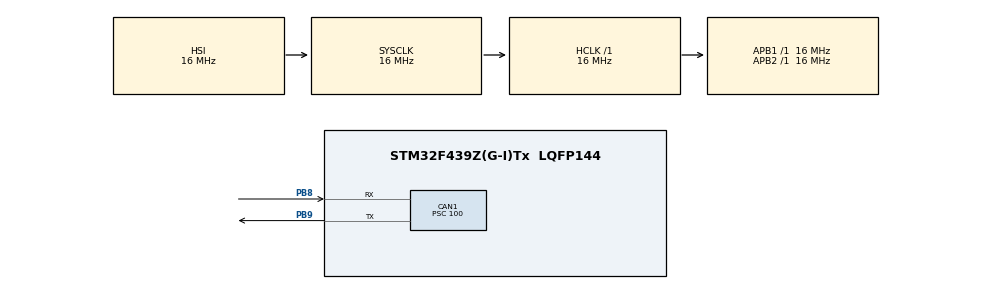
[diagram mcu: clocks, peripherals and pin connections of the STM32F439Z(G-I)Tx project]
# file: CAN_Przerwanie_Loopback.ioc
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CAN1.BS1=CAN_BS1_13TQ
CAN1.BS2=CAN_BS2_2TQ
CAN1.CalculateBaudRate=10000
CAN1.CalculateTimeBit=100000.00
CAN1.CalculateTimeQuantum=6250.0
CAN1.Mode=CAN_MODE_LOOPBACK
CAN1.Prescaler=100
Mcu.Family=STM32F4
Mcu.Name=STM32F439Z(G-I)Tx
Mcu.Package=LQFP144
NVIC.CAN1_RX0_IRQn=true\:0\:0\:false\:false\:true\:true\:true
NVIC.PriorityGroup=NVIC_PRIORITYGROUP_4
PA13.Mode=Serial_Wire
PA13.Signal=SYS_JTMS-SWDIO
PA14.Mode=Serial_Wire
PA14.Signal=SYS_JTCK-SWCLK
PB8.Mode=CAN_Activate
PB8.Signal=CAN1_RX
PB9.Mode=CAN_Activate
PB9.Signal=CAN1_TX
ProjectManager.HeapSize=0x200
ProjectManager.StackSize=0x400
ProjectManager.TargetToolchain=STM32CubeIDE
RCC.48MHZClocksFreq_Value=48000000
RCC.AHBFreq_Value=16000000
RCC.APB1Freq_Value=16000000
RCC.APB2Freq_Value=16000000
RCC.CortexFreq_Value=16000000
RCC.HSE_VALUE=25000000
RCC.HSI_VALUE=16000000
RCC.LSE_VALUE=32768
RCC.SYSCLKFreq_VALUE=16000000
RCC.VCOOutputFreq_Value=192000000
board=custom

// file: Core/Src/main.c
/* USER CODE BEGIN Header */
/**
  ******************************************************************************
  * @file           : main.c
  * @brief          : Main program body
  ******************************************************************************
  * @attention
  *
  * <h2><center>&copy; Copyright (c) 2021 STMicroelectronics.
  * All rights reserved.</center></h2>
  *
  * This software component is licensed by ST under BSD 3-Clause license,
  * the "License"; You may not use this file except in compliance with the
  * License. You may obtain a copy of the License at:
  *                        opensource.org/licenses/BSD-3-Clause
  *
  ******************************************************************************
  */
/* USER CODE END Header */
#include "main.h"

CAN_HandleTypeDef hcan1;

void SystemClock_Config(void);
static void MX_GPIO_Init(void);
static void MX_CAN1_Init(void);

/* USER CODE BEGIN 0 */

CAN_TxHeaderTypeDef TxHeader;
CAN_RxHeaderTypeDef RxHeader;

uint32_t TxMailbox;

uint8_t TxData [8];
uint8_t RxData [8];

uint8_t count =0;

void HAL_CAN_RxFifo0MsgPendingCallback(CAN_HandleTypeDef *hcan1){

	HAL_CAN_GetRxMessage(hcan1, CAN_RX_FIFO0,&RxHeader, RxData);
	count++;
}
/* USER CODE END 0 */

int main(void)
{

  /* MCU Configuration--------------------------------------------------------*/

  /* Reset of all peripherals, Initializes the Flash interface and the Systick. */
   HAL_Init();

  /* Configure the system clock */
  SystemClock_Config();

  /* Initialize all configured peripherals */
  MX_GPIO_Init();
  MX_CAN1_Init();
  /* USER CODE BEGIN 2 */

  HAL_CAN_Start(&hcan1);

  HAL_CAN_ActivateNotification(&hcan1, CAN_IT_RX_FIFO0_MSG_PENDING);

  TxHeader.DLC = 1;
  TxHeader.ExtId = 0;
  TxHeader.IDE = CAN_ID_STD;
  TxHeader.RTR = CAN_RTR_DATA;
  TxHeader.StdId = 0x123;
  TxHeader.TransmitGlobalTime = DISABLE;

  TxData [0]= 0xf3;
  HAL_CAN_AddTxMessage(&hcan1, &TxHeader, TxData, &TxMailbox);

  /* USER CODE END 2 */

  /* Infinite loop */
  while (1)
  {

  }
}

void SystemClock_Config(void)
{
  RCC_OscInitTypeDef RCC_OscInitStruct = {0};
  RCC_ClkInitTypeDef RCC_ClkInitStruct = {0};

  /** Configure the main internal regulator output voltage
  */
  __HAL_RCC_PWR_CLK_ENABLE();
  __HAL_PWR_VOLTAGESCALING_CONFIG(PWR_REGULATOR_VOLTAGE_SCALE3);
  /** Initializes the RCC Oscillators according to the specified parameters
  * in the RCC_OscInitTypeDef structure.
  */
  RCC_OscInitStruct.OscillatorType = RCC_OSCILLATORTYPE_HSI;
  RCC_OscInitStruct.HSIState = RCC_HSI_ON;
  RCC_OscInitStruct.HSICalibrationValue = RCC_HSICALIBRATION_DEFAULT;
  RCC_OscInitStruct.PLL.PLLState = RCC_PLL_NONE;
  if (HAL_RCC_OscConfig(&RCC_OscInitStruct) != HAL_OK)
  {
    Error_Handler();
  }
  /** Initializes the CPU, AHB and APB buses clocks
  */
  RCC_ClkInitStruct.ClockType = RCC_CLOCKTYPE_HCLK|RCC_CLOCKTYPE_SYSCLK
                              |RCC_CLOCKTYPE_PCLK1|RCC_CLOCKTYPE_PCLK2;
  RCC_ClkInitStruct.SYSCLKSource = RCC_SYSCLKSOURCE_HSI;
  RCC_ClkInitStruct.AHBCLKDivider = RCC_SYSCLK_DIV1;
  RCC_ClkInitStruct.APB1CLKDivider = RCC_HCLK_DIV1;
  RCC_ClkInitStruct.APB2CLKDivider = RCC_HCLK_DIV1;

  if (HAL_RCC_ClockConfig(&RCC_ClkInitStruct, FLASH_LATENCY_0) != HAL_OK)
  {
    Error_Handler();
  }
}

static void MX_CAN1_Init(void)
{

  hcan1.Instance = CAN1;
  hcan1.Init.Prescaler = 100;
  hcan1.Init.Mode = CAN_MODE_LOOPBACK;
  hcan1.Init.SyncJumpWidth = CAN_SJW_1TQ;
  hcan1.Init.TimeSeg1 = CAN_BS1_13TQ;
  hcan1.Init.TimeSeg2 = CAN_BS2_2TQ;
  hcan1.Init.TimeTriggeredMode = DISABLE;
  hcan1.Init.AutoBusOff = DISABLE;
  hcan1.Init.AutoWakeUp = DISABLE;
  hcan1.Init.AutoRetransmission = DISABLE;
  hcan1.Init.ReceiveFifoLocked = DISABLE;
  hcan1.Init.TransmitFifoPriority = DISABLE;
  if (HAL_CAN_Init(&hcan1) != HAL_OK)
  {
    Error_Handler();
  }
  /* USER CODE BEGIN CAN1_Init 2 */

  CAN_FilterTypeDef canfilterconfig;

  canfilterconfig.FilterActivation = CAN_FILTER_ENABLE;  // aktywowanie filtrów
  canfilterconfig.FilterBank = 10;  // dla jednego CAn liczba od 0 do 13
  canfilterconfig.FilterFIFOAssignment =CAN_RX_FIFO0; // dane przychodzące trafią do FIFO 0
  canfilterconfig.FilterIdHigh = 0x103<<5;// rejestry zawierają równiez pola dla rozszeżonego ID dlatego trzeba przesunąc o 5 bitów
  canfilterconfig.FilterIdLow = 0x0000;
  canfilterconfig.FilterMaskIdHigh = 0x100<<5;
  canfilterconfig.FilterMaskIdLow = 0x0000;
  canfilterconfig.FilterMode = CAN_FILTERMODE_IDMASK; // tryb litra albo maska albo lista dopuszczonych ID
  canfilterconfig.FilterScale= CAN_FILTERSCALE_32BIT; // ID w rejestrze maski będzie miało wielkość 32 bitów
  canfilterconfig.SlaveStartFilterBank = 0; // niepotrzebne gdy używamy tylko jednego CAN

  HAL_CAN_ConfigFilter(&hcan1, &canfilterconfig);

  /* USER CODE END CAN1_Init 2 */

}

static void MX_GPIO_Init(void)
{

  /* GPIO Ports Clock Enable */
  __HAL_RCC_GPIOA_CLK_ENABLE();
  __HAL_RCC_GPIOB_CLK_ENABLE();

}

void Error_Handler(void)
{
  __disable_irq();
  while (1)
  {
  }
}

/************************ (C) COPYRIGHT STMicroelectronics *****END OF FILE****/
